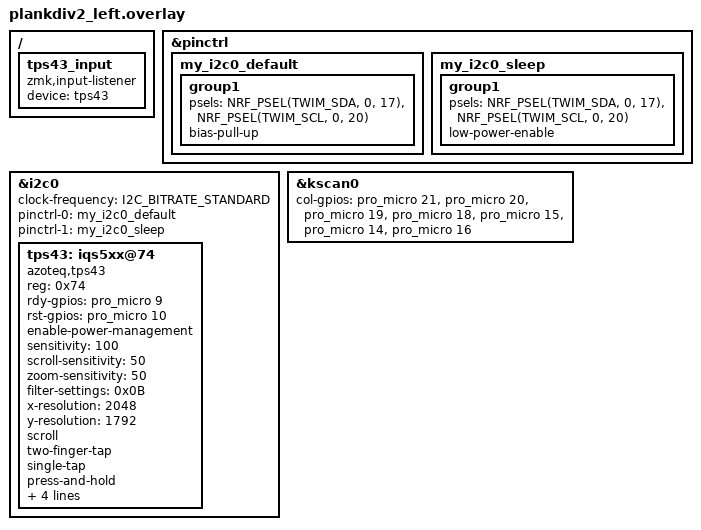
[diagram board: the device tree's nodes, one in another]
/*
 * Copyright (c) 2020 The ZMK Contributors
 *
 * SPDX-License-Identifier: MIT
 */

#include "plankdiv2.dtsi"

/ {
    tps43_input: tps43_input {
        compatible = "zmk,input-listener";
        device = <&tps43>;
    };
};

&pinctrl {
    my_i2c0_default: my_i2c0_default {
        group1 {
            psels = <NRF_PSEL(TWIM_SDA, 0, 17)>,   /* Pro Micro 2 */
                    <NRF_PSEL(TWIM_SCL, 0, 20)>;   /* Pro Micro 3 */
            bias-pull-up;                          /* Enforces internal pull-up */
        };
    };

    my_i2c0_sleep: my_i2c0_sleep {
        group1 {
            psels = <NRF_PSEL(TWIM_SDA, 0, 17)>,
                    <NRF_PSEL(TWIM_SCL, 0, 20)>;
            low-power-enable;
        };
    };
};

&i2c0 {
    status = "okay";
    clock-frequency = <I2C_BITRATE_STANDARD>;
    pinctrl-0 = <&my_i2c0_default>;
    pinctrl-1 = <&my_i2c0_sleep>;
    pinctrl-names = "default", "sleep";

    tps43: iqs5xx@74 {
        compatible = "azoteq,tps43";
        reg = <0x74>;
        status = "okay";

        /* GPIO connections */
        rdy-gpios = <&pro_micro 9 GPIO_ACTIVE_HIGH>;  /* RDY pin */
        rst-gpios = <&pro_micro 10 GPIO_ACTIVE_HIGH>;  /* RST pin */

        enable-power-management;

        sensitivity = <100>;           /* 100% = normal state */
        scroll-sensitivity = <50>;     /* 50% = normal state */
        zoom-sensitivity = <50>;       /* 50% = normal state */

        filter-settings=<0x0B>;        /* See filter description in `available settings` */
        // filter-dynamic-bottom=<7>;     /* Dynamic filter bottom beta (optional) */
        // filter-dynamic-lower=<6>;      /* Dynamic filter lower speed (optional) */
        // filter-dynamic-upper=<0xFA>;   /* Dynamic filter upper speed (optional) */
        x-resolution=<2048>;            /* X resolution in pixels */
        y-resolution=<1792>;            /* Y resolution in pixels */

        // swipe-initial-distance=<500>;          /* Swipe initial distance in px (optional) */
        // swipe-initial-time=<200>;              /* Swipe initial time in ms (optional) */
        // swipe-angle=<20>;                      /* Max swipe angle in degrees (optional) */
        // swipe-consecutive-distance=<200>;      /* Swipe consecutive distance in px (optional) */
        // swipe-consecutive-time=<150>;          /* Swipe consecutive time in ms (optional) */
        // scroll-initial-distance=<100>;         /* Scroll initial distance in px (optional) */
        // scroll-angle=<30>;                     /* Max scroll angle in degrees (optional) */
        // zoom-initial-distance=<100>;           /* Zoom initial distance in px (optional) */
        // zoom-consecutive-distance=<50>;        /* Zoom consecutive distance in px (optional) */

        scroll;
        two-finger-tap;
        single-tap;
        press-and-hold;
        swipes;
        zoom;

        switch-xy;
        invert-scroll-y;
    };
};

&kscan0 {
    col-gpios
        = <&pro_micro 21 GPIO_ACTIVE_HIGH>
        , <&pro_micro 20 GPIO_ACTIVE_HIGH>
        , <&pro_micro 19 GPIO_ACTIVE_HIGH>
        , <&pro_micro 18 GPIO_ACTIVE_HIGH>
        , <&pro_micro 15 GPIO_ACTIVE_HIGH>
        , <&pro_micro 14 GPIO_ACTIVE_HIGH>
        , <&pro_micro 16 GPIO_ACTIVE_HIGH>
        ;
};
